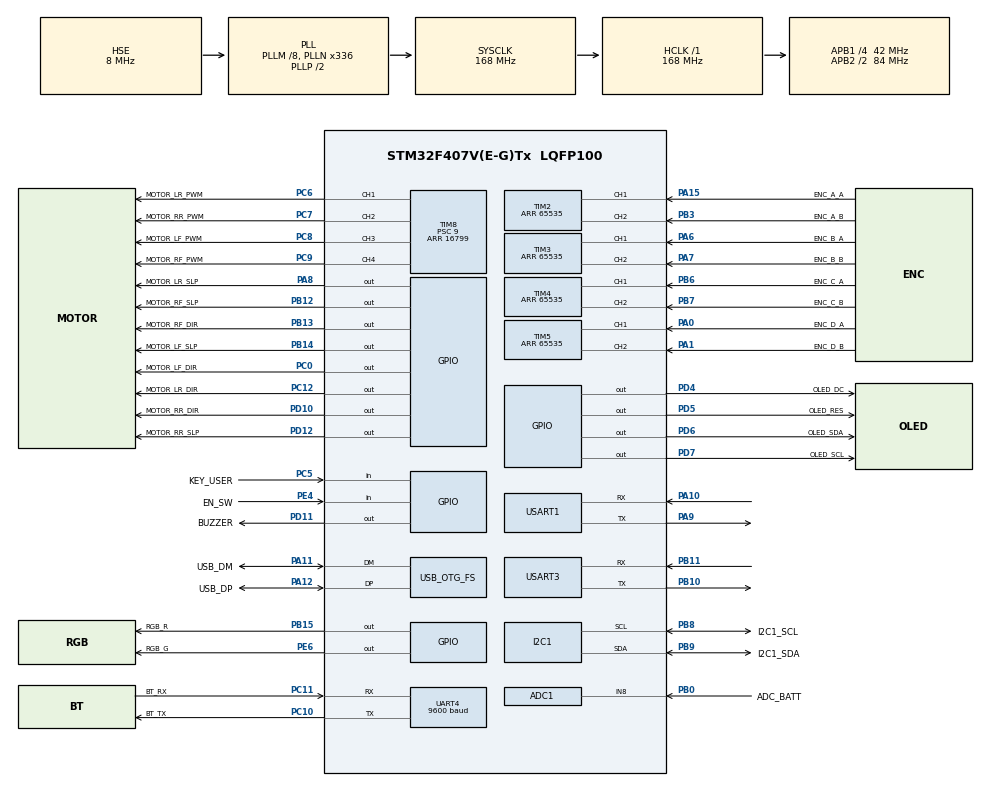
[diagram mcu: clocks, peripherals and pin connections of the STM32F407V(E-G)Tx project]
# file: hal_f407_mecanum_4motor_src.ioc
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ADC1.Channel-0\#ChannelRegularConversion=ADC_CHANNEL_8
ADC1.NbrOfConversionFlag=1
ADC1.Rank-0\#ChannelRegularConversion=1
ADC1.SamplingTime-0\#ChannelRegularConversion=ADC_SAMPLETIME_480CYCLES
ADC1.master=1
FREERTOS.INCLUDE_xTimerPendFunctionCall=1
FREERTOS.Tasks01=defaultTask,24,128,StartDefaultTask,Default,NULL,Dynamic,NULL,NULL
FREERTOS.configCHECK_FOR_STACK_OVERFLOW=2
FREERTOS.configTOTAL_HEAP_SIZE=40960
FREERTOS.configUSE_MALLOC_FAILED_HOOK=1
Mcu.Family=STM32F4
Mcu.Name=STM32F407V(E-G)Tx
Mcu.Package=LQFP100
NVIC.OTG_FS_IRQn=true\:5\:0\:false\:false\:true\:true\:true\:true\:true
NVIC.PriorityGroup=NVIC_PRIORITYGROUP_4
NVIC.TIM6_DAC_IRQn=true\:15\:0\:false\:false\:true\:false\:false\:true\:true
NVIC.TimeBase=TIM6_DAC_IRQn
NVIC.TimeBaseIP=TIM6
PA0-WKUP.GPIO_Label=ENC_D_A
PA0-WKUP.GPIO_PuPd=GPIO_PULLUP
PA0-WKUP.Signal=S_TIM5_CH1
PA1.GPIO_Label=ENC_D_B
PA1.GPIO_PuPd=GPIO_PULLUP
PA1.Signal=S_TIM5_CH2
PA10.Mode=Asynchronous
PA10.Signal=USART1_RX
PA11.GPIO_Label=USB_DM
PA11.Mode=Host_Only
PA11.Signal=USB_OTG_FS_DM
PA12.GPIO_Label=USB_DP
PA12.Mode=Host_Only
PA12.Signal=USB_OTG_FS_DP
PA13.Mode=Serial_Wire
PA13.Signal=SYS_JTMS-SWDIO
PA14.Mode=Serial_Wire
PA14.Signal=SYS_JTCK-SWCLK
PA15.GPIO_Label=ENC_A_A
PA15.GPIO_PuPd=GPIO_PULLUP
PA15.Signal=S_TIM2_CH1_ETR
PA6.GPIO_Label=ENC_B_A
PA6.GPIO_PuPd=GPIO_PULLUP
PA6.Signal=S_TIM3_CH1
PA7.GPIO_Label=ENC_B_B
PA7.GPIO_PuPd=GPIO_PULLUP
PA7.Signal=S_TIM3_CH2
PA8.GPIO_Label=MOTOR_LR_SLP
PA8.GPIO_Speed=GPIO_SPEED_FREQ_LOW
PA8.PinState=GPIO_PIN_RESET
PA8.Signal=GPIO_Output
PA9.Mode=Asynchronous
PA9.Signal=USART1_TX
PB0.GPIO_Label=ADC_BATT
PB0.Signal=ADCx_IN8
PB10.Mode=Asynchronous
PB10.Signal=USART3_TX
PB11.Mode=Asynchronous
PB11.Signal=USART3_RX
PB12.GPIO_Label=MOTOR_RF_SLP
PB12.GPIO_Speed=GPIO_SPEED_FREQ_LOW
PB12.PinState=GPIO_PIN_RESET
PB12.Signal=GPIO_Output
PB13.GPIO_Label=MOTOR_RF_DIR
PB13.GPIO_Speed=GPIO_SPEED_FREQ_HIGH
PB13.Signal=GPIO_Output
PB14.GPIO_Label=MOTOR_LF_SLP
PB14.GPIO_Speed=GPIO_SPEED_FREQ_LOW
PB14.PinState=GPIO_PIN_RESET
PB14.Signal=GPIO_Output
PB15.GPIO_Label=RGB_R
PB15.Signal=GPIO_Output
PB3.GPIO_Label=ENC_A_B
PB3.GPIO_PuPd=GPIO_PULLUP
PB3.Signal=S_TIM2_CH2
PB6.GPIO_Label=ENC_C_A
PB6.GPIO_PuPd=GPIO_PULLUP
PB6.Signal=S_TIM4_CH1
PB7.GPIO_Label=ENC_C_B
PB7.GPIO_PuPd=GPIO_PULLUP
PB7.Signal=S_TIM4_CH2
PB8.GPIO_Label=I2C1_SCL
PB8.Mode=I2C
PB8.Signal=I2C1_SCL
PB9.GPIO_Label=I2C1_SDA
PB9.Mode=I2C
PB9.Signal=I2C1_SDA
PC0.GPIO_Label=MOTOR_LF_DIR
PC0.GPIO_Speed=GPIO_SPEED_FREQ_HIGH
PC0.Signal=GPIO_Output
PC10.GPIO_Label=BT_TX
PC10.Mode=Asynchronous
PC10.Signal=UART4_TX
PC11.GPIO_Label=BT_RX
PC11.Mode=Asynchronous
PC11.Signal=UART4_RX
PC12.GPIO_Label=MOTOR_LR_DIR
PC12.GPIO_Speed=GPIO_SPEED_FREQ_HIGH
PC12.Signal=GPIO_Output
PC5.GPIO_Label=KEY_USER
PC5.GPIO_PuPd=GPIO_PULLUP
PC5.Signal=GPIO_Input
PC6.GPIO_Label=MOTOR_LR_PWM
PC6.GPIO_Speed=GPIO_SPEED_FREQ_HIGH
PC6.Signal=S_TIM8_CH1
PC7.GPIO_Label=MOTOR_RR_PWM
PC7.GPIO_Speed=GPIO_SPEED_FREQ_HIGH
PC7.Signal=S_TIM8_CH2
PC8.GPIO_Label=MOTOR_LF_PWM
PC8.GPIO_Speed=GPIO_SPEED_FREQ_HIGH
PC8.Signal=S_TIM8_CH3
PC9.GPIO_Label=MOTOR_RF_PWM
PC9.GPIO_Speed=GPIO_SPEED_FREQ_HIGH
PC9.Signal=S_TIM8_CH4
PD10.GPIO_Label=MOTOR_RR_DIR
PD10.GPIO_Speed=GPIO_SPEED_FREQ_HIGH
PD10.Signal=GPIO_Output
PD11.GPIO_Label=BUZZER
PD11.Signal=GPIO_Output
PD12.GPIO_Label=MOTOR_RR_SLP
PD12.GPIO_Speed=GPIO_SPEED_FREQ_LOW
PD12.PinState=GPIO_PIN_RESET
PD12.Signal=GPIO_Output
PD4.GPIO_Label=OLED_DC
PD4.GPIO_Speed=GPIO_SPEED_FREQ_HIGH
PD4.Signal=GPIO_Output
PD5.GPIO_Label=OLED_RES
PD5.GPIO_Speed=GPIO_SPEED_FREQ_HIGH
PD5.PinState=GPIO_PIN_SET
PD5.Signal=GPIO_Output
PD6.GPIO_Label=OLED_SDA
PD6.GPIO_Speed=GPIO_SPEED_FREQ_HIGH
PD6.PinState=GPIO_PIN_SET
PD6.Signal=GPIO_Output
PD7.GPIO_Label=OLED_SCL
PD7.GPIO_Speed=GPIO_SPEED_FREQ_HIGH
PD7.PinState=GPIO_PIN_SET
PD7.Signal=GPIO_Output
PE4.GPIO_Label=EN_SW
PE4.GPIO_PuPd=GPIO_PULLUP
PE4.Signal=GPIO_Input
PE6.GPIO_Label=RGB_G
PE6.Signal=GPIO_Output
PH0-OSC_IN.Mode=HSE-External-Oscillator
PH0-OSC_IN.Signal=RCC_OSC_IN
PH1-OSC_OUT.Mode=HSE-External-Oscillator
PH1-OSC_OUT.Signal=RCC_OSC_OUT
ProjectManager.HeapSize=0x200
ProjectManager.StackSize=0x400
ProjectManager.TargetToolchain=Makefile
RCC.48MHZClocksFreq_Value=48000000
RCC.AHBFreq_Value=168000000
RCC.APB1CLKDivider=RCC_HCLK_DIV4
RCC.APB1Freq_Value=42000000
RCC.APB1TimFreq_Value=84000000
RCC.APB2CLKDivider=RCC_HCLK_DIV2
RCC.APB2Freq_Value=84000000
RCC.APB2TimFreq_Value=168000000
RCC.CortexFreq_Value=168000000
RCC.HCLKFreq_Value=168000000
RCC.HSE_VALUE=8000000
RCC.HSI_VALUE=16000000
RCC.LSE_VALUE=32768
RCC.PLLM=8
RCC.PLLN=336
RCC.PLLQ=7
RCC.SYSCLKFreq_VALUE=168000000
RCC.SYSCLKSource=RCC_SYSCLKSOURCE_PLLCLK
RCC.VCOOutputFreq_Value=336000000
SH.ADCx_IN8.0=ADC1_IN8,IN8
SH.S_TIM2_CH1_ETR.0=TIM2_CH1,Encoder_Interface
SH.S_TIM2_CH2.0=TIM2_CH2,Encoder_Interface
SH.S_TIM3_CH1.0=TIM3_CH1,Encoder_Interface
SH.S_TIM3_CH2.0=TIM3_CH2,Encoder_Interface
SH.S_TIM4_CH1.0=TIM4_CH1,Encoder_Interface
SH.S_TIM4_CH2.0=TIM4_CH2,Encoder_Interface
SH.S_TIM5_CH1.0=TIM5_CH1,Encoder_Interface
SH.S_TIM5_CH2.0=TIM5_CH2,Encoder_Interface
SH.S_TIM8_CH1.0=TIM8_CH1,PWM Generation1 CH1
SH.S_TIM8_CH2.0=TIM8_CH2,PWM Generation2 CH2
SH.S_TIM8_CH3.0=TIM8_CH3,PWM Generation3 CH3
SH.S_TIM8_CH4.0=TIM8_CH4,PWM Generation4 CH4
TIM8.AutoReloadPreload=TIM_AUTORELOAD_PRELOAD_ENABLE
TIM8.AutomaticOutput=TIM_AUTOMATICOUTPUT_ENABLE
TIM2.Encoder\ Mode=TIM_ENCODERMODE_TI12
TIM2.Period=65535
TIM3.Encoder\ Mode=TIM_ENCODERMODE_TI12
TIM3.Period=65535
TIM4.Encoder\ Mode=TIM_ENCODERMODE_TI12
TIM4.Period=65535
TIM5.Encoder\ Mode=TIM_ENCODERMODE_TI12
TIM5.Period=65535
TIM8.Channel-PWM\ Generation1\ CH1=TIM_CHANNEL_1
TIM8.Channel-PWM\ Generation2\ CH2=TIM_CHANNEL_2
TIM8.Channel-PWM\ Generation3\ CH3=TIM_CHANNEL_3
TIM8.Channel-PWM\ Generation4\ CH4=TIM_CHANNEL_4
TIM8.Period=16799
TIM8.Prescaler=9
UART4.BaudRate=9600
UART4.VirtualMode=Asynchronous
USART1.VirtualMode=VM_ASYNC
USART3.VirtualMode=VM_ASYNC
USB_HOST.SW_VBUS_DRIVE_HID_FS=true
USB_HOST.USBH_HandleTypeDef-HID_FS=hUsbHostFS
USB_HOST.VirtualModeFS=Hid
USB_OTG_FS.VirtualMode=Host_Only
USB_OTG_FS.phy_itface=HCD_PHY_EMBEDDED
VP_FREERTOS_VS_CMSIS_V2.Mode=CMSIS_V2
VP_SYS_VS_tim6.Mode=TIM6
VP_USB_HOST_VS_USB_HOST_HID_FS.Mode=HID_FS
board=custom

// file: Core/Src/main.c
/* USER CODE BEGIN Header */
/**
  ******************************************************************************
  * @file           : main.c
  * @brief          : Main program body
  ******************************************************************************
  * @attention
  *
  * Copyright (c) 2026 STMicroelectronics.
  * All rights reserved.
  *
  * This software is licensed under terms that can be found in the LICENSE file
  * in the root directory of this software component.
  * If no LICENSE file comes with this software, it is provided AS-IS.
  *
  ******************************************************************************
  */
/* USER CODE END Header */
#include "main.h"
#include "cmsis_os.h"
#include "adc.h"
#include "i2c.h"
#include "tim.h"
#include "usart.h"
#include "usb_host.h"
#include "gpio.h"

/* USER CODE BEGIN Includes */
#include "motor_drive.h"
/* USER CODE END Includes */

void SystemClock_Config(void);
void MX_FREERTOS_Init(void);

int main(void)
{

  /* MCU Configuration--------------------------------------------------------*/

  /* Reset of all peripherals, Initializes the Flash interface and the Systick. */
  HAL_Init();

  /* Configure the system clock */
  SystemClock_Config();

  /* Initialize all configured peripherals */
  MX_GPIO_Init();
  MX_ADC1_Init();
  MX_I2C1_Init();
  MX_TIM8_Init();
  MX_UART4_Init();
  MX_USART1_UART_Init();
  MX_USART3_UART_Init();
  MX_TIM2_Init();
  MX_TIM3_Init();
  MX_TIM4_Init();
  MX_TIM5_Init();
  /* USER CODE BEGIN 2 */
  MotorDrive_Init();  /* 启动 PWM 与编码器, 电机默认睡眠 */
  RosLink_Init();     /* 启动 USART1 接收 */
  /* USER CODE END 2 */

  /* Init scheduler */
  osKernelInitialize();  /* Call init function for freertos objects (in cmsis_os2.c) */
  MX_FREERTOS_Init();

  /* Start scheduler */
  osKernelStart();

  /* We should never get here as control is now taken by the scheduler */

  /* Infinite loop */
  while (1)
  {

  }
}

void SystemClock_Config(void)
{
  RCC_OscInitTypeDef RCC_OscInitStruct = {0};
  RCC_ClkInitTypeDef RCC_ClkInitStruct = {0};

  /** Configure the main internal regulator output voltage
  */
  __HAL_RCC_PWR_CLK_ENABLE();
  __HAL_PWR_VOLTAGESCALING_CONFIG(PWR_REGULATOR_VOLTAGE_SCALE1);

  /** Initializes the RCC Oscillators according to the specified parameters
  * in the RCC_OscInitTypeDef structure.
  */
  RCC_OscInitStruct.OscillatorType = RCC_OSCILLATORTYPE_HSE;
  RCC_OscInitStruct.HSEState = RCC_HSE_ON;
  RCC_OscInitStruct.PLL.PLLState = RCC_PLL_ON;
  RCC_OscInitStruct.PLL.PLLSource = RCC_PLLSOURCE_HSE;
  RCC_OscInitStruct.PLL.PLLM = 8;
  RCC_OscInitStruct.PLL.PLLN = 336;
  RCC_OscInitStruct.PLL.PLLP = RCC_PLLP_DIV2;
  RCC_OscInitStruct.PLL.PLLQ = 7;
  if (HAL_RCC_OscConfig(&RCC_OscInitStruct) != HAL_OK)
  {
    Error_Handler();
  }

  /** Initializes the CPU, AHB and APB buses clocks
  */
  RCC_ClkInitStruct.ClockType = RCC_CLOCKTYPE_HCLK|RCC_CLOCKTYPE_SYSCLK
                              |RCC_CLOCKTYPE_PCLK1|RCC_CLOCKTYPE_PCLK2;
  RCC_ClkInitStruct.SYSCLKSource = RCC_SYSCLKSOURCE_PLLCLK;
  RCC_ClkInitStruct.AHBCLKDivider = RCC_SYSCLK_DIV1;
  RCC_ClkInitStruct.APB1CLKDivider = RCC_HCLK_DIV4;
  RCC_ClkInitStruct.APB2CLKDivider = RCC_HCLK_DIV2;

  if (HAL_RCC_ClockConfig(&RCC_ClkInitStruct, FLASH_LATENCY_5) != HAL_OK)
  {
    Error_Handler();
  }
}

void HAL_TIM_PeriodElapsedCallback(TIM_HandleTypeDef *htim)
{
  if (htim->Instance == TIM6)
  {
    HAL_IncTick();
  }
}

void Error_Handler(void)
{
  __disable_irq();
  while (1)
  {
  }
}

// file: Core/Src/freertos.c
/* USER CODE BEGIN Header */
/**
  ******************************************************************************
  * File Name          : freertos.c
  * Description        : Code for freertos applications
  ******************************************************************************
  * @attention
  *
  * Copyright (c) 2026 STMicroelectronics.
  * All rights reserved.
  *
  * This software is licensed under terms that can be found in the LICENSE file
  * in the root directory of this software component.
  * If no LICENSE file comes with this software, it is provided AS-IS.
  *
  ******************************************************************************
  */
/* USER CODE END Header */

#include "FreeRTOS.h"
#include "task.h"
#include "main.h"
#include "cmsis_os.h"

/* USER CODE BEGIN Includes */
#include "motor_drive.h"
/* USER CODE END Includes */

/* Definitions for defaultTask */
osThreadId_t defaultTaskHandle;
const osThreadAttr_t defaultTask_attributes = {
  .name = "defaultTask",
  .stack_size = 128 * 4,
  .priority = (osPriority_t) osPriorityNormal,
};

void StartDefaultTask(void *argument);

extern void MX_USB_HOST_Init(void);
void MX_FREERTOS_Init(void); /* (MISRA C 2004 rule 8.1) */

/* Hook prototypes */
void vApplicationStackOverflowHook(xTaskHandle xTask, signed char *pcTaskName);
void vApplicationMallocFailedHook(void);

/* USER CODE BEGIN 4 */
void vApplicationStackOverflowHook(xTaskHandle xTask, signed char *pcTaskName)
{
   /* Run time stack overflow checking is performed if
   configCHECK_FOR_STACK_OVERFLOW is defined to 1 or 2. This hook function is
   called if a stack overflow is detected. */
}
/* USER CODE END 4 */

/* USER CODE BEGIN 5 */
void vApplicationMallocFailedHook(void)
{
   /* vApplicationMallocFailedHook() will only be called if
   configUSE_MALLOC_FAILED_HOOK is set to 1 in FreeRTOSConfig.h. It is a hook
   function that will get called if a call to pvPortMalloc() fails.
   pvPortMalloc() is called internally by the kernel whenever a task, queue,
   timer or semaphore is created. It is also called by various parts of the
   demo application. If heap_1.c or heap_2.c are used, then the size of the
   heap available to pvPortMalloc() is defined by configTOTAL_HEAP_SIZE in
   FreeRTOSConfig.h, and the xPortGetFreeHeapSize() API function can be used
   to query the size of free heap space that remains (although it does not
   provide information on how the remaining heap might be fragmented). */
}
/* USER CODE END 5 */

void MX_FREERTOS_Init(void) {

  /* Create the thread(s) */
  /* creation of defaultTask */
  defaultTaskHandle = osThreadNew(StartDefaultTask, NULL, &defaultTask_attributes);

  /* USER CODE BEGIN RTOS_THREADS */
  /* ROS 串口通信与电机控制任务 */
  static const osThreadAttr_t rosLinkTask_attributes = {
    .name = "rosLink",
    .stack_size = 1024,
    .priority = (osPriority_t) osPriorityNormal,
  };
  osThreadNew(RosLink_Task, NULL, &rosLinkTask_attributes);
  /* USER CODE END RTOS_THREADS */

}

void StartDefaultTask(void *argument)
{
  /* init code for USB_HOST */
  MX_USB_HOST_Init();
  for(;;)
  {
    osDelay(1);
  }
}
